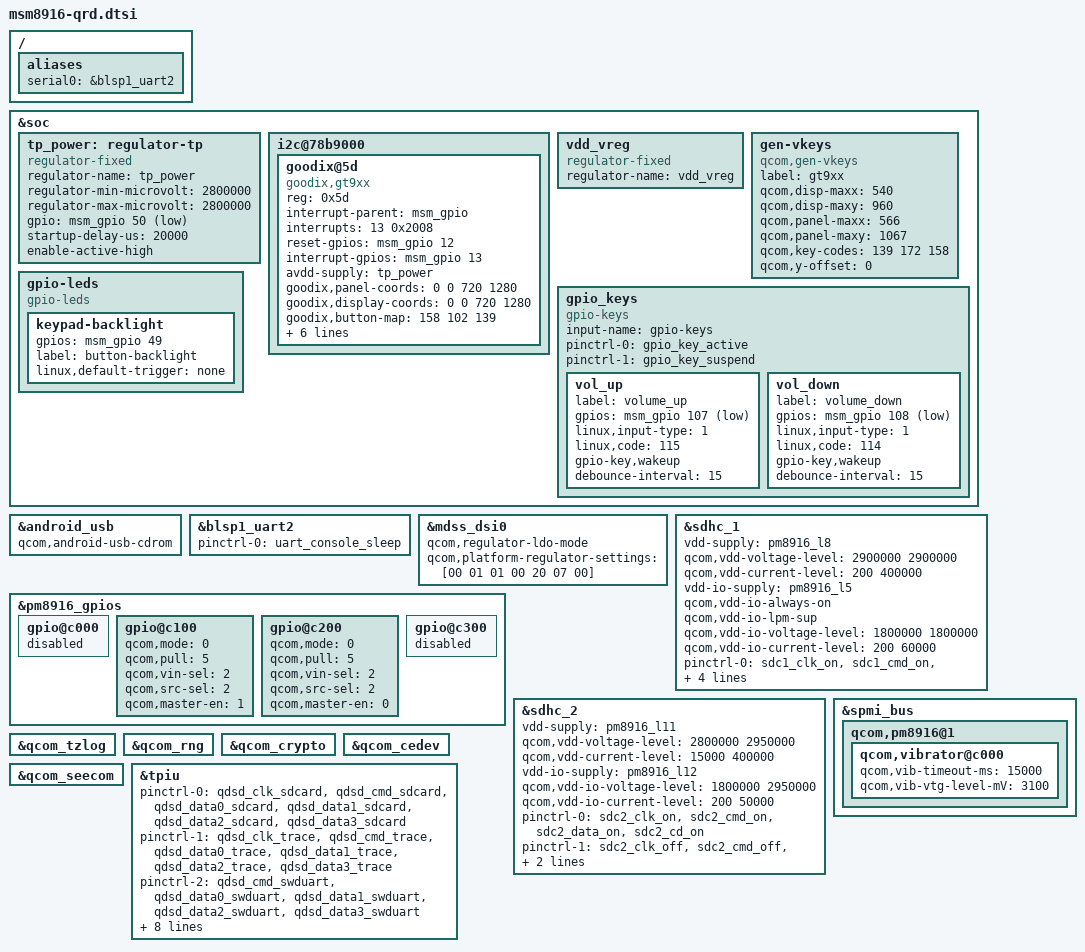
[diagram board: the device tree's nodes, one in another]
/* Copyright (c) 2015, The Linux Foundation. All rights reserved.
 *
 * This program is free software; you can redistribute it and/or modify
 * it under the terms of the GNU General Public License version 2 and
 * only version 2 as published by the Free Software Foundation.
 *
 * This program is distributed in the hope that it will be useful,
 * but WITHOUT ANY WARRANTY; without even the implied warranty of
 * MERCHANTABILITY or FITNESS FOR A PARTICULAR PURPOSE.  See the
 * GNU General Public License for more details.
 */

#include "msm8916.dtsi"
#include "msm8916-pinctrl.dtsi"

/ {
	aliases {
		serial0 = &blsp1_uart2;
	};
};

&soc {
	tp_power: regulator-tp {
		compatible = "regulator-fixed";
		regulator-name = "tp_power";
		regulator-min-microvolt = <2800000>;
		regulator-max-microvolt = <2800000>;
		gpio = <&msm_gpio 50 0x01>;
		startup-delay-us = <20000>;
		enable-active-high;
	};
	
	i2c@78b9000 { /* BLSP1 QUP5 */
		goodix@5d {
			compatible = "goodix,gt9xx";
			reg = <0x5d>;
			interrupt-parent = <&msm_gpio>; 
			interrupts = <13 0x2008>;  
			reset-gpios = <&msm_gpio 12 0x00>;
			interrupt-gpios = <&msm_gpio 13 0x00>;
			avdd-supply =<&tp_power>;
			goodix,panel-coords = <0 0 720 1280>;
			goodix,display-coords = <0 0 720 1280>;			
			goodix,button-map= <158 102 139>;
			goodix,product-id = "915";
			goodix,cfg-data0 = [
				41 E0 01 20 03 0A 05 C1 01 08 
				28 05 50 32 03 05 00 00 FF 7F 
				00 00 00 00 00 00 14 88 27 0A 
				2C 2E B5 06 00 00 01 9B 33 11 
				3C 01 00 00 00 03 64 32 00 00 
				CA 1E 5A 94 C5 02 07 00 00 04 
				A8 21 00 88 29 00 6D 34 00 58 
				41 00 48 51 00 48 0F 2F 47 00 
				F7 40 30 FF FF 27 00 00 00 00 
				00 00 00 00 00 00 00 00 00 00 
				00 00 00 00 00 00 00 19 00 00 
				46 00 08 0A 0C 0E 10 12 14 16 
				18 1A 00 00 00 00 00 00 00 00 
				00 00 00 00 00 00 00 00 00 00 
				00 00 28 24 22 20 1F 1E 1D 0C 
				0A 08 06 05 04 02 00 00 00 00 
				00 00 00 00 00 00 00 00 00 00 
				00 FF FF FF FF FF FF FF FF FF 
				FF FF FF FF B4 01];
			goodix,cfg-data1 = [
				41 E0 01 20 03 0A 05 C1 01 08 
				28 05 50 32 03 05 00 00 FF 7F 
				00 00 00 00 00 00 14 88 27 0A 
				2C 2E B5 06 00 00 01 9B 33 11 
				3C 01 00 00 00 03 64 32 00 00 
				CA 1E 5A 94 C5 02 07 00 00 04 
				A8 21 00 88 29 00 6D 34 00 58 
				41 00 48 51 00 48 0F 2F 47 00 
				F7 40 30 FF FF 27 00 00 00 00 
				00 00 00 00 00 00 00 00 00 00 
				00 00 00 00 00 00 00 19 00 00 
				46 00 08 0A 0C 0E 10 12 14 16 
				18 1A 00 00 00 00 00 00 00 00 
				00 00 00 00 00 00 00 00 00 00 
				00 00 28 24 22 20 1F 1E 1D 0C 
				0A 08 06 05 04 02 00 00 00 00 
				00 00 00 00 00 00 00 00 00 00 
				00 FF FF FF FF FF FF FF FF FF 
				FF FF FF FF B4 01];
			goodix,fw_name = "gtp_fw.bin";
		};
	};

	vdd_vreg: vdd_vreg {
		compatible = "regulator-fixed";
		status = "ok";
		regulator-name = "vdd_vreg";
	};

	gen-vkeys {
		compatible = "qcom,gen-vkeys";
		label = "gt9xx";
                qcom,disp-maxx = <540>;
 		qcom,disp-maxy = <960>;
 		qcom,panel-maxx = <566>;	
                qcom,panel-maxy = <1067>; 
		qcom,key-codes = <139 172 158>;
		qcom,y-offset = <0>;
	};

	gpio-leds {
		compatible = "gpio-leds";
		keypad-backlight {
			gpios = <&msm_gpio 49 0>;
			label = "button-backlight";
			linux,default-trigger = "none";
		};
	};
};

&android_usb {
	qcom,android-usb-cdrom;
};

&blsp1_uart2 {
	status = "ok";
	pinctrl-names = "default";
	pinctrl-0 = <&uart_console_sleep>;
};

&mdss_dsi0 {
	qcom,regulator-ldo-mode;
	qcom,platform-regulator-settings = [00 01 01 00 20 07 00];
};

&soc {
	gpio_keys {
		compatible = "gpio-keys";
		input-name = "gpio-keys";
		pinctrl-names = "tlmm_gpio_key_active","tlmm_gpio_key_suspend";
		pinctrl-0 = <&gpio_key_active>;
		pinctrl-1 = <&gpio_key_suspend>;

		vol_up {
			label = "volume_up";
			gpios = <&msm_gpio 107 0x1>;
			linux,input-type = <1>;
			linux,code = <115>;
			gpio-key,wakeup;
			debounce-interval = <15>;
		};

		vol_down {
			label = "volume_down";
			gpios = <&msm_gpio 108 0x1>;
			linux,input-type = <1>;
			linux,code = <114>;
			gpio-key,wakeup;
			debounce-interval = <15>;
		};

	};
};

&pm8916_gpios {
	gpio@c000 { /* GPIO 1 */
		/* Battery UICC Alarm */
		status = "disabled";
	};

	gpio@c100 { /* GPIO 2 */
		/* NFC_CLK_REQ */
		qcom,mode = <0>; /* QPNP_PIN_MODE_DIG_IN */
		qcom,pull = <5>; /* QPNP_PIN_PULL_NO */
		qcom,vin-sel = <2>; /* QPNP_PIN_VIN2 */
		qcom,src-sel = <2>; /* QPNP_PIN_SEL_FUNC_1 */
		qcom,master-en = <1>;
	};

	gpio@c200 { /* GPIO 3 */
		/* External regulator control for WTR */
		qcom,mode = <0>; /* QPNP_PIN_MODE_DIG_IN */
		qcom,pull = <5>; /* QPNP_PIN_PULL_NO */
		qcom,vin-sel = <2>; /* QPNP_PIN_VIN2 */
		qcom,src-sel = <2>; /* QPNP_PIN_SEL_FUNC_1 */
		qcom,master-en = <0>;
	};

	gpio@c300 { /* GPIO 4 */
		/* External regulator control for APC */
		status = "disabled";
	};
};

&sdhc_1 {
	vdd-supply = <&pm8916_l8>;
	qcom,vdd-voltage-level = <2900000 2900000>;
	qcom,vdd-current-level = <200 400000>;

	vdd-io-supply = <&pm8916_l5>;
	qcom,vdd-io-always-on;
	qcom,vdd-io-lpm-sup;
	qcom,vdd-io-voltage-level = <1800000 1800000>;
	qcom,vdd-io-current-level = <200 60000>;

	pinctrl-names = "active", "sleep";
	pinctrl-0 = <&sdc1_clk_on &sdc1_cmd_on &sdc1_data_on>;
	pinctrl-1 = <&sdc1_clk_off &sdc1_cmd_off &sdc1_data_off>;

	qcom,nonremovable;

	status = "ok";
};

&sdhc_2 {
	vdd-supply = <&pm8916_l11>;
	qcom,vdd-voltage-level = <2800000 2950000>;
	qcom,vdd-current-level = <15000 400000>;

	vdd-io-supply = <&pm8916_l12>;
	qcom,vdd-io-voltage-level = <1800000 2950000>;
	qcom,vdd-io-current-level = <200 50000>;

	pinctrl-names = "active", "sleep";
	pinctrl-0 = <&sdc2_clk_on &sdc2_cmd_on &sdc2_data_on &sdc2_cd_on>;
	pinctrl-1 = <&sdc2_clk_off &sdc2_cmd_off &sdc2_data_off &sdc2_cd_off>;
	qcom,nonremovable;
	status = "ok";
};

&spmi_bus {
	qcom,pm8916@1 {
		qcom,vibrator@c000 {
			status = "okay";
			qcom,vib-timeout-ms = <15000>;
			qcom,vib-vtg-level-mV = <3100>;
		};
	};
};

&qcom_tzlog {
	status = "okay";
};

&qcom_rng {
	status = "okay";
};

&qcom_crypto {
	status = "okay";
};

&qcom_cedev {
	status = "okay";
};

&qcom_seecom {
	status = "okay";
};

/* CoreSight */
&tpiu {
      pinctrl-names = "sdcard", "trace", "swduart",
		      "swdtrc", "jtag", "spmi";
       /* NIDnT */
      pinctrl-0 = <&qdsd_clk_sdcard &qdsd_cmd_sdcard
                  &qdsd_data0_sdcard &qdsd_data1_sdcard
                  &qdsd_data2_sdcard &qdsd_data3_sdcard>;
      pinctrl-1 = <&qdsd_clk_trace &qdsd_cmd_trace
                  &qdsd_data0_trace &qdsd_data1_trace
                  &qdsd_data2_trace &qdsd_data3_trace>;
      pinctrl-2 = <&qdsd_cmd_swduart &qdsd_data0_swduart
                  &qdsd_data1_swduart &qdsd_data2_swduart
                  &qdsd_data3_swduart>;
      pinctrl-3 = <&qdsd_clk_swdtrc &qdsd_cmd_swdtrc
                  &qdsd_data0_swdtrc &qdsd_data1_swdtrc
                  &qdsd_data2_swdtrc &qdsd_data3_swdtrc>;
      pinctrl-4 = <&qdsd_cmd_jtag &qdsd_data0_jtag
                  &qdsd_data1_jtag &qdsd_data2_jtag
                  &qdsd_data3_jtag>;
      pinctrl-5 = <&qdsd_clk_spmi &qdsd_cmd_spmi
                  &qdsd_data0_spmi &qdsd_data3_spmi>;
};
